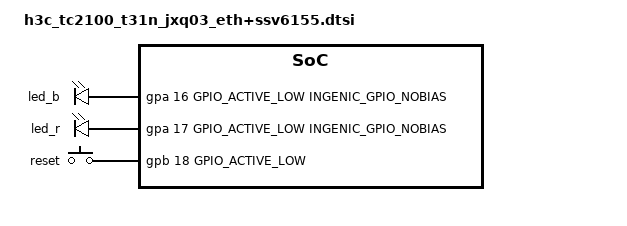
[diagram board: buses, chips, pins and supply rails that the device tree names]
// H3C TC2100 (T31N, JXQ03, ETH, SSV6155) per-board GPIO definitions.
// Injected into the kernel 4.4+ device tree; ignored on 3.10.

#include <dt-bindings/gpio/gpio.h>
#include <dt-bindings/input/input.h>
#include <dt-bindings/pinctrl/ingenic-pinctrl.h>

/ {
	gpio-leds {
		compatible = "gpio-leds";

		led_b {
			label = "led_b";
			gpios = <&gpa 16 GPIO_ACTIVE_LOW INGENIC_GPIO_NOBIAS>;
			default-state = "off";
		};

		led_r {
			label = "led_r";
			gpios = <&gpa 17 GPIO_ACTIVE_LOW INGENIC_GPIO_NOBIAS>;
			default-state = "off";
		};
	};
};

/* Card detect; the family tree carries the reference pin. */
&msc0 {
	ingenic,cd-gpios = <&gpb 17 GPIO_ACTIVE_LOW INGENIC_GPIO_PULLUP>;
};

/ {
	gpio-keys {
		compatible = "gpio-keys";
		label = "gpio-keys";

		reset {
			label = "reset";
			linux,code = <KEY_ENTER>;
			gpios = <&gpb 18 GPIO_ACTIVE_LOW INGENIC_GPIO_PULLUP>;
		};
	};
};
